AUTOSAR XML (schema 4-3-0)
package /Impl_SWC_CARB_ARPkg
  swc implementation Impl_SWC_CARB_type: programming-language=C, sw-version=1.0.0, vendor-id=0, behavior=SWC_CARB_type_IB
    code-descriptors:
      code SRC: artifact-descriptors=autosar-engineering-object={short-label=EngObject, category=SWSRC}
    resource consumption ResourceConsumption
      memory section MEM_SWC_CARB_CAL: size=0, sw-addrmethod=CAL, symbol=CAL
      memory section MEM_SWC_CARB_CODE: size=0, sw-addrmethod=CODE, symbol=CODE
package /SWC_CARB_ARPkg
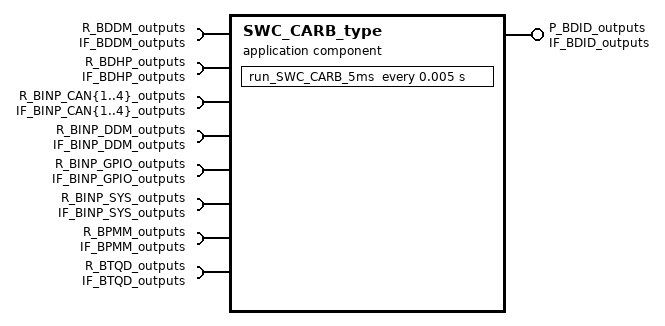
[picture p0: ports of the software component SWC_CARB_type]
  application sw component type SWC_CARB_type
    provide port P_BDID_outputs: provided-interface=IF_BDID_outputs
    11 x require port:
      R_BDDM_outputs: required-interface=IF_BDDM_outputs
      R_BDHP_outputs: required-interface=IF_BDHP_outputs
      R_BINP_CAN{1..4}_outputs: required-interface=IF_BINP_CAN{1..4}_outputs
      R_BINP_DDM_outputs: required-interface=IF_BINP_DDM_outputs
      R_BINP_GPIO_outputs: required-interface=IF_BINP_GPIO_outputs
      R_BINP_SYS_outputs: required-interface=IF_BINP_SYS_outputs
      R_BPMM_outputs: required-interface=IF_BPMM_outputs
      R_BTQD_outputs: required-interface=IF_BTQD_outputs
    behavior SWC_CARB_type_IB: data-type-mapping=AppModeTypeMap, handle-termination-and-restart=NO-SUPPORT
      timing event TE_CARB_5ms: start-on-event=run_SWC_CARB_5ms, period=0.005
      runnable run_SWC_CARB_5ms
        data-receive-point-by-arguments:
          11 x access:
            drparg_BDDM_outputs: accessed-variable=R_BDDM_outputs.BDDM_outputs
            drparg_BDHP_outputs: accessed-variable=R_BDHP_outputs.BDHP_outputs
            drparg_BINP_CAN{1..4}_outputs: accessed-variable=R_BINP_CAN{1..4}_outputs.BINP_CAN{1..4}_outputs
            drparg_BINP_DDM_outputs: accessed-variable=R_BINP_DDM_outputs.BINP_DDM_outputs
            drparg_BINP_GPIO_outputs: accessed-variable=R_BINP_GPIO_outputs.BINP_GPIO_outputs
            drparg_BINP_SYS_outputs: accessed-variable=R_BINP_SYS_outputs.BINP_SYS_outputs
            drparg_BPMM_outputs: accessed-variable=R_BPMM_outputs.BPMM_outputs
            drparg_BTQD_outputs: accessed-variable=R_BTQD_outputs.BTQD_outputs
        data-send-points:
          access dsp_BDID_outputs: accessed-variable=P_BDID_outputs.BDID_outputs
